# STM32F031K6U7 register map
File version: 1.0
Registers are 32-bit, access not given, reset 0x0 unless marked. A register's access mark holds for its fields unless they carry their own. Offsets are from the block's base; [hi:lo] are bit positions; {n}, {i} and the like mark numbered series; 'fields as' and 'values as' point back to an identical list.

## WWDG
Base 0x40002C00
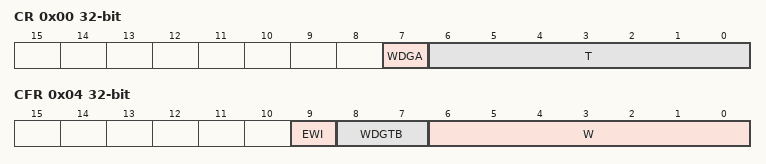
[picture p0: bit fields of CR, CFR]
0x00 CR
  [7] WDGA, [6:0] T
0x04 CFR
  [9] EWI, [8:7] WDGTB, [6:0] W
0x08 SR
  [0] EWIF

## IWDG
Base 0x40003000
0x00 KR
  [15:0] KEY
0x04 PR
  [2:0] PR
0x08 RLR
  [11:0] RL
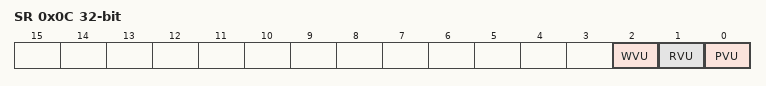
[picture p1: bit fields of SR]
0x0C SR
  [2] WVU, [1] RVU, [0] PVU
0x10 WINR
  [11:0] WIN

## I2C1
Base 0x40005400
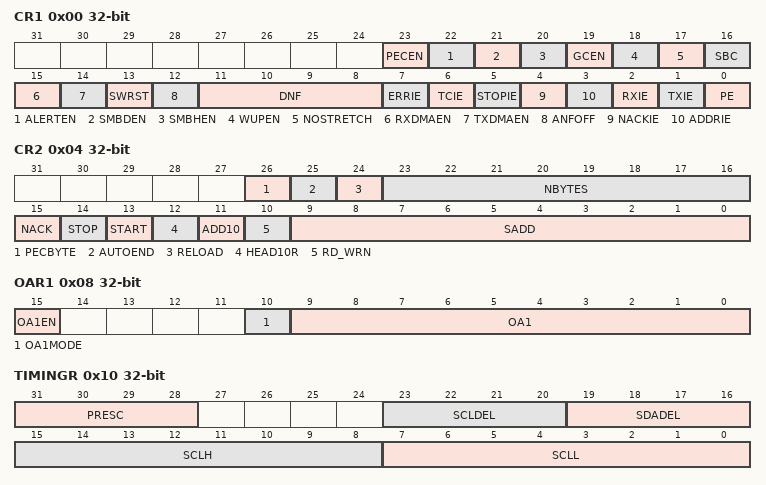
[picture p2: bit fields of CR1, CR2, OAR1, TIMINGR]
0x00 CR1
  [23] PECEN, [22] ALERTEN, [21] SMBDEN, [20] SMBHEN, [19] GCEN, [18] WUPEN, [17] NOSTRETCH, [16] SBC, [15] RXDMAEN, [14] TXDMAEN, [13] SWRST, [12] ANFOFF, [11:8] DNF, [7] ERRIE, [6] TCIE, [5] STOPIE, [4] NACKIE, [3] ADDRIE, [2] RXIE, [1] TXIE, [0] PE
0x04 CR2
  [26] PECBYTE, [25] AUTOEND, [24] RELOAD, [23:16] NBYTES, [15] NACK, [14] STOP, [13] START, [12] HEAD10R, [11] ADD10, [10] RD_WRN, [9:0] SADD
0x08 OAR1
  [15] OA1EN, [10] OA1MODE, [9:0] OA1
0x0C OAR2
  [15] OA2EN, [10] OA2MASK04, [10:9] OA2MASK06, [10:8] OA2MSK, [7:1] OA2
0x10 TIMINGR
  [31:28] PRESC, [23:20] SCLDEL, [19:16] SDADEL, [15:8] SCLH, [7:0] SCLL
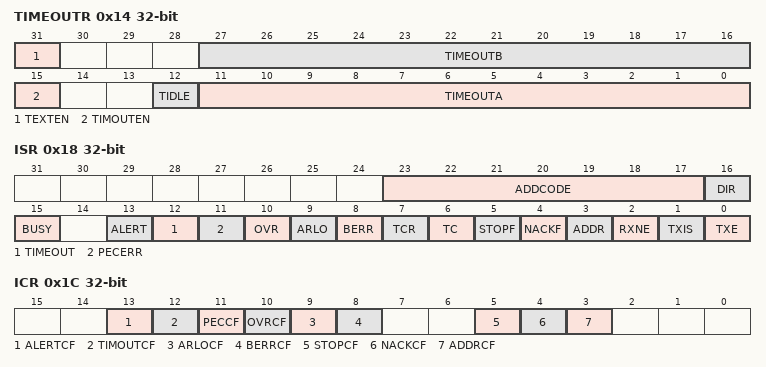
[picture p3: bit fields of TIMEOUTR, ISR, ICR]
0x14 TIMEOUTR
  [31] TEXTEN, [27:16] TIMEOUTB, [15] TIMOUTEN, [12] TIDLE, [11:0] TIMEOUTA
0x18 ISR
  [23:17] ADDCODE, [16] DIR, [15] BUSY, [13] ALERT, [12] TIMEOUT, [11] PECERR, [10] OVR, [9] ARLO, [8] BERR, [7] TCR, [6] TC, [5] STOPF, [4] NACKF, [3] ADDR, [2] RXNE, [1] TXIS, [0] TXE
0x1C ICR
  [13] ALERTCF, [12] TIMOUTCF, [11] PECCF, [10] OVRCF, [9] ARLOCF, [8] BERRCF, [5] STOPCF, [4] NACKCF, [3] ADDRCF
0x20 PECR
  [7:0] PEC
0x24 RXDR
  [7:0] RXDATA
0x28 TXDR
  [7:0] TXDATA

## PWR
Base 0x40007000
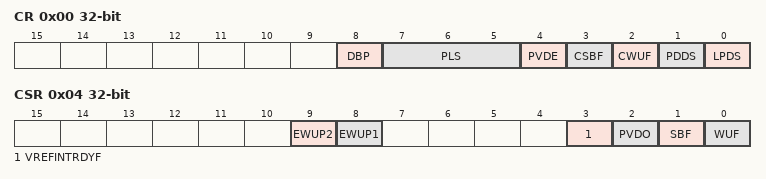
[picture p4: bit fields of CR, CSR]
0x00 CR
  [8] DBP, [7:5] PLS, [4] PVDE, [3] CSBF, [2] CWUF, [1] PDDS, [0] LPDS
0x04 CSR
  [9] EWUP2, [8] EWUP1, [3] VREFINTRDYF, [2] PVDO, [1] SBF, [0] WUF

## SYSCFG
Base 0x40010000
0x00 CFGR1
  [23] I2C_FMP_PA10, [22] I2C_FMP_PA9, [20] I2C_FMP_I2C1, [n+10] I2C_FMP_PB{n} (n=6..9), [12] TIM17_DMA_RMP, [11] TIM16_DMA_RMP, [10] USART1RX_DMA_RMP, [9] USART1TX_DMA_RMP, [12:8] DMA_RMP, [1:0] MEM_MODE
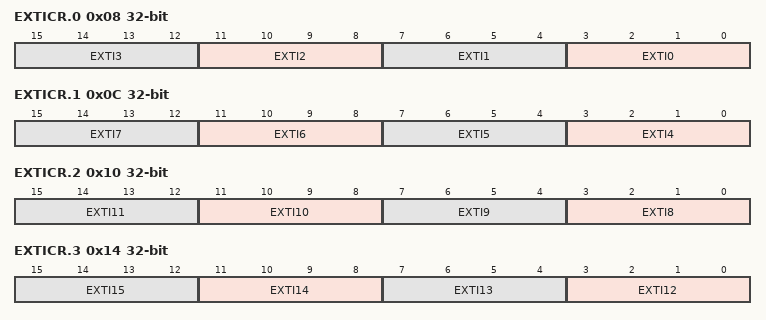
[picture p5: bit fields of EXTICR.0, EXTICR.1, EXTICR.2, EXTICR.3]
0x08 EXTICR.0
  [4n+3:4n] EXTI{n} (n=0..3)
0x0C EXTICR.1
  [4n-13:4n-16] EXTI{n} (n=4..7)
0x10 EXTICR.2
  [4n-29:4n-32] EXTI{n} (n=8..11)
0x14 EXTICR.3
  [4n-45:4n-48] EXTI{n} (n=12..15)
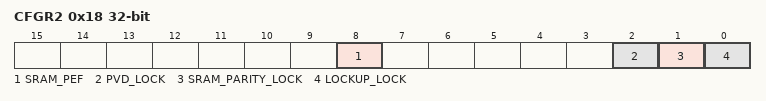
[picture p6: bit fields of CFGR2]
0x18 CFGR2
  [8] SRAM_PEF, [2] PVD_LOCK, [1] SRAM_PARITY_LOCK, [0] LOCKUP_LOCK

## EXTI
Base 0x40010400
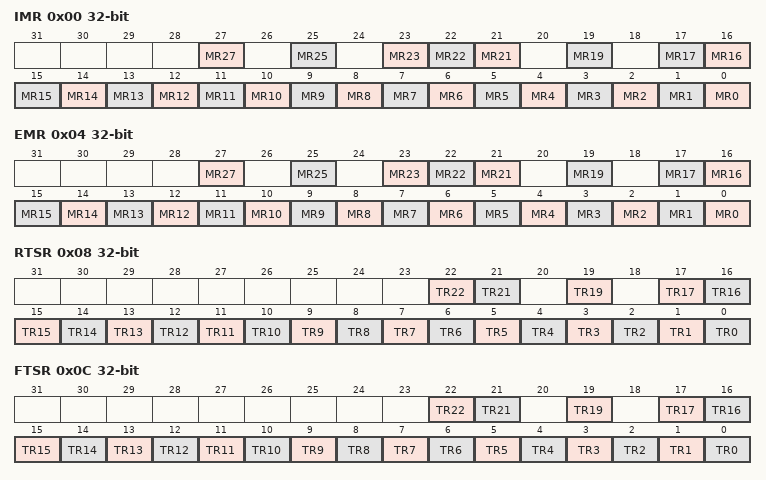
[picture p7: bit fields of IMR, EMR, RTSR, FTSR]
0x00 IMR
  [27] MR27, [25] MR25, [23] MR23, [22] MR22, [21] MR21, [19] MR19, [n] MR{n} (n=0..17)
0x04 EMR
  fields as IMR
0x08 RTSR
  [22] TR22, [21] TR21, [19] TR19, [n] TR{n} (n=0..17)
0x0C FTSR
  [22] TR22, [21] TR21, [19] TR19, [n] TR{n} (n=0..17)
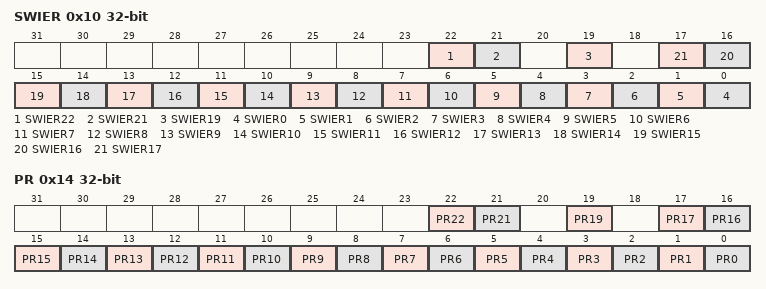
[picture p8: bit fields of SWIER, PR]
0x10 SWIER
  [22] SWIER22, [21] SWIER21, [19] SWIER19, [n] SWIER{n} (n=0..17)
0x14 PR
  [22] PR22, [21] PR21, [19] PR19, [n] PR{n} (n=0..17)

## ADC1
Base 0x40012400
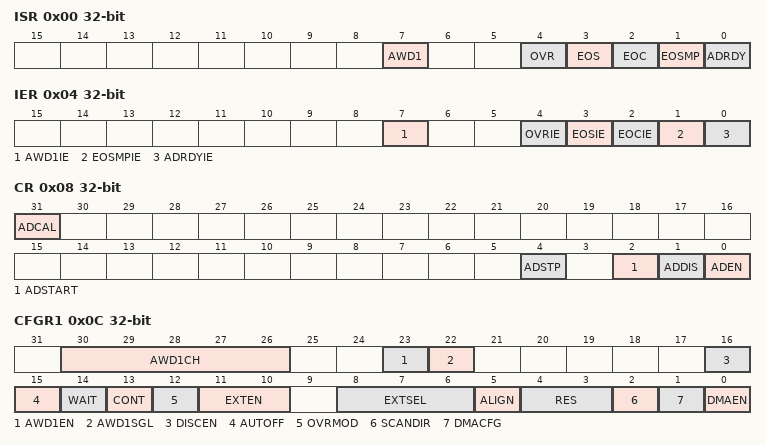
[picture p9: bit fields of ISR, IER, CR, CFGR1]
0x00 ISR
  [7] AWD1, [4] OVR, [3] EOS, [2] EOC, [1] EOSMP, [0] ADRDY
0x04 IER
  [7] AWD1IE, [4] OVRIE, [3] EOSIE, [2] EOCIE, [1] EOSMPIE, [0] ADRDYIE
0x08 CR
  [31] ADCAL, [4] ADSTP, [2] ADSTART, [1] ADDIS, [0] ADEN
0x0C CFGR1
  [30:26] AWD1CH, [23] AWD1EN, [22] AWD1SGL, [16] DISCEN, [15] AUTOFF, [14] WAIT, [13] CONT, [12] OVRMOD, [11:10] EXTEN, [8:6] EXTSEL, [5] ALIGN, [4:3] RES, [2] SCANDIR, [1] DMACFG, [0] DMAEN
0x10 CFGR2
  [31:30] CKMODE
0x14 SMPR
  [2:0] SMP
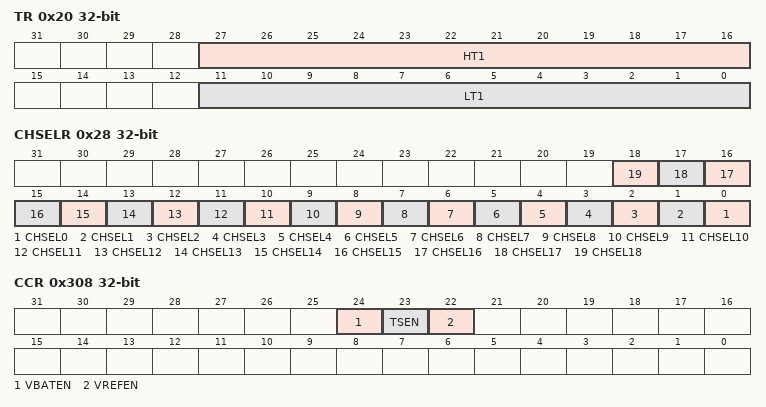
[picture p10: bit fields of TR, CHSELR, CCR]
0x20 TR
  [27:16] HT1, [11:0] LT1
0x28 CHSELR
  [n] CHSEL{n} (n=0..18)
0x40 DR
  [15:0] DATA
0x308 CCR
  [24] VBATEN, [23] TSEN, [22] VREFEN

## SPI1
Base 0x40013000
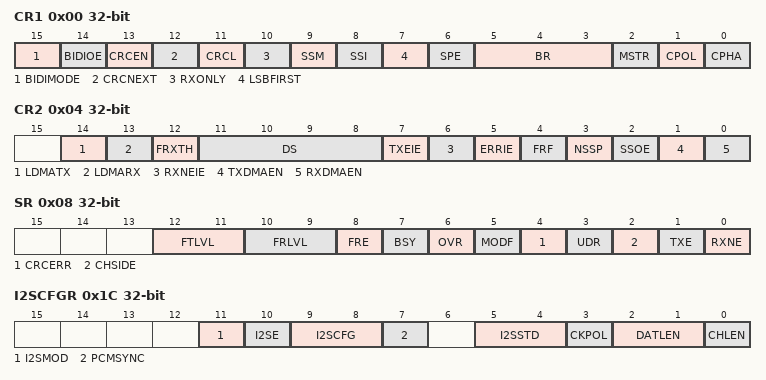
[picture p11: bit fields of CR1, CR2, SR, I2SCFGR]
0x00 CR1
  [15] BIDIMODE, [14] BIDIOE, [13] CRCEN, [12] CRCNEXT, [11] CRCL, [10] RXONLY, [9] SSM, [8] SSI, [7] LSBFIRST, [6] SPE, [5:3] BR, [2] MSTR, [1] CPOL, [0] CPHA
0x04 CR2
  [14] LDMATX, [13] LDMARX, [12] FRXTH, [11:8] DS, [7] TXEIE, [6] RXNEIE, [5] ERRIE, [4] FRF, [3] NSSP, [2] SSOE, [1] TXDMAEN, [0] RXDMAEN
0x08 SR
  [12:11] FTLVL, [10:9] FRLVL, [8] FRE, [7] BSY, [6] OVR, [5] MODF, [4] CRCERR, [3] UDR, [2] CHSIDE, [1] TXE, [0] RXNE
0x0C DR
0x10 CRCPR
  [31:0] CRCPOLY
0x14 RXCRCR
  [31:0] RXCRC
0x18 TXCRCR
  [31:0] TXCRC
0x1C I2SCFGR
  [11] I2SMOD, [10] I2SE, [9:8] I2SCFG, [7] PCMSYNC, [5:4] I2SSTD, [3] CKPOL, [2:1] DATLEN, [0] CHLEN
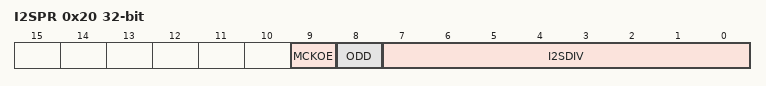
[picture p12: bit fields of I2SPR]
0x20 I2SPR
  [9] MCKOE, [8] ODD, [7:0] I2SDIV
